# APM32F00x register map
File version: 1.0
CPU: CM0+ r0p1, little endian, no MPU, no FPU, 4 interrupt priority bits
Registers are 32-bit, read-write, reset 0x0 unless marked. A register's access mark holds for its fields unless they carry their own. Offsets are from the block's base; [hi:lo] are bit positions.

## USART1 — Universal asynchronous receiver transmitter
Base 0x40003400
Same registers: USART2 0x40001400, USART3 0x40004800
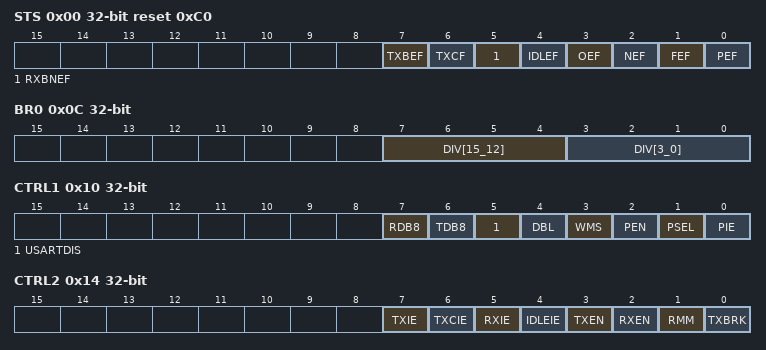
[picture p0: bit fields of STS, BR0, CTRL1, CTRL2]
0x00 STS access per field reset 0xC0 — Status register
  [7] TXBEF ro — Transmit data register empty
  [6] TXCF rw — Transmission complete
  [5] RXBNEF rw — Read data register not empty
  [4] IDLEF ro — IDLE line detected
  [3] OEF ro — Overrun error
  [2] NEF ro — Noise error flag
  [1] FEF ro — Framing error
  [0] PEF ro — Parity error
0x04 DATA
  [7:0] DATA — Data value
0x08 BR1 — Baud rate register 1
  [7:0] DIV[11_4] — LSB mantissa of USARTxDIV [11:4] mask
0x0C BR0 — Baud rate register 2
  [7:4] DIV[15_12] — MSB mantissa of USARTxDIV [15:12] mask
  [3:0] DIV[3_0] — Fraction bits of USARTxDIV [3:0] mask
0x10 CTRL1 — Control register 1
  [7] RDB8 — Receive Data bit 8
  [6] TDB8 — Transmit data bit 8
  [5] USARTDIS — USARTx Disable (for low power consumption)
  [4] DBL — Word length mask
  [3] WMS — Wake-up method mask
  [2] PEN — Parity Control Enable mask
  [1] PSEL — USARTx Parity Selection
  [0] PIE — USARTx Parity Interrupt Enable mask
0x14 CTRL2 — Control register 2
  [7] TXIE — Transmit Buffer Empty Interrupt Enable
  [6] TXCIE — Transmit Complete Interrupt Enable
  [5] RXIE — Receive Buffer Not Empty Interrupt Enable
  [4] IDLEIE — IDLE Interrupt Enable
  [3] TXEN — Transmit Enable
  [2] RXEN — Receive Enable
  [1] RMM — Receive Mute Mode Enable
  [0] TXBRK — Transmit Break Frame
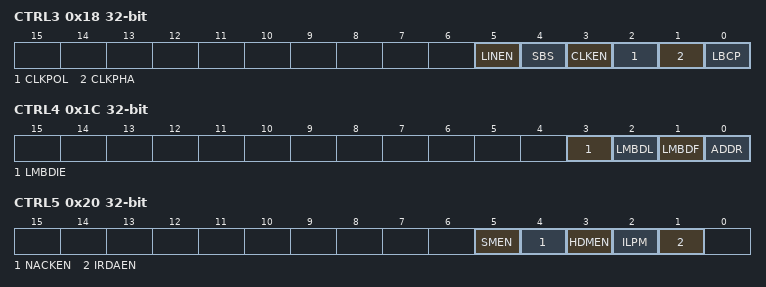
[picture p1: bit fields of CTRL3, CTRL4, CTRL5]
0x18 CTRL3 — Control register 3
  [5] LINEN — LIN Mode Enable
  [4] SBS — STOP Bit Configure
  [3] CLKEN — Clock Enable（CK pin）
  [2] CLKPOL — Clock Polarity Configure
  [1] CLKPHA — Clock Phase Configure
  [0] LBCP — Last Bit Clock Pulse Output Enable
0x1C CTRL4 — Control register 4
  [3] LMBDIE — LIN Break Detection Interrupt Enable
  [2] LMBDL — LIN Break Detection Length Configure
  [1] LMBDF — LIN Break Detected Flag
  [0] ADDR — USART Device Node Address Setup
0x20 CTRL5 — Control register 5
  [5] SMEN — Smartcard Function Enable
  [4] NACKEN — NACK Transmit Enable During Parity Error in Smartcard Function
  [3] HDMEN — Half-duplex Mode Enable
  [2] ILPM — IrDA Low-power Mode Enable
  [1] IRDAEN — IrDA Function Enable
0x24 GTS — Guard time and register
  [15:8] GTS — Guard Time Value Setup
0x28 PSC — USART1 prescaler register
  [15:8] PSC — Prescaler Factor Setup
0x2C SW — USART2/USART3 switch register
  [0] SW — Open USART
0x30 IOSW — USART3 IO switch register
  [0] SW — Open USART IO Port

## I2C — Inter-integrated circuit interface
Base 0x40003000
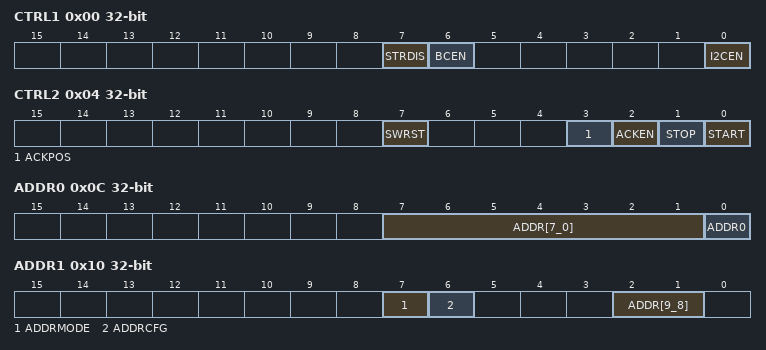
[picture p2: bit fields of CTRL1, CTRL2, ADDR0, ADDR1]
0x00 CTRL1 — Control register 1
  [7] STRDIS — Slave Mode Clock Stretching Disable
  [6] BCEN — Slave Responds Broadcast Enable
  [0] I2CEN — I2C Enable
0x04 CTRL2 — Control register 2
  [7] SWRST — Software Configure I2C under Reset State
  [3] ACKPOS — Acknowledge Position Configure
  [2] ACKEN — Acknowledge Transfer Enable
  [1] STOP — Stop Bit Transfer
  [0] START — Start Bit Transfer
0x08 CLKFREQ — Frequency Control register
  [5:0] FREQ — I2C Clock Frequency Configure
0x0C ADDR0 — Slave address register 0
  [7:1] ADDR[7_0] — Slave Address Setup
  [0] ADDR0 — Slave Address Setup
0x10 ADDR1 — Slave address register 1
  [7] ADDRMODE — Slave Address Mode Configure
  [6] ADDRCFG — Address Mode Configure
  [2:1] ADDR[9_8] — Slave Address Setup
0x18 DATA
  [7:0] DATA
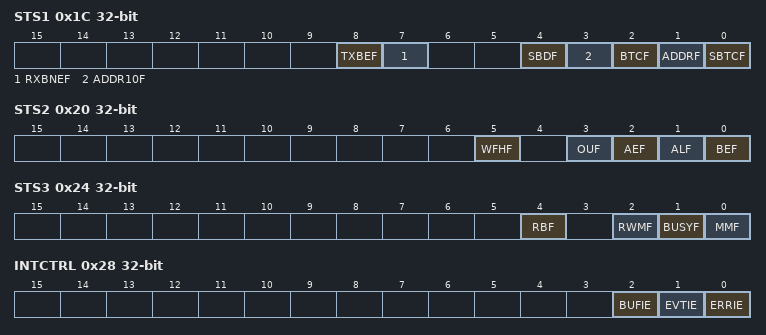
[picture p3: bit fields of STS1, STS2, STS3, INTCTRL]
0x1C STS1 ro — Status register 1
  [8] TXBEF — Transmit Buffer Empty Flag
  [7] RXBNEF — Receive Buffer Not Empty Flag
  [4] SBDF — Stop Bit Detection Flag
  [3] ADDR10F — 10-Bit Address Header Sent Flag
  [2] BTCF — Byte Transfer Complete Flag
  [1] ADDRF — Address Transfer Complete /Receive Match Flag
  [0] SBTCF — Start Bit Sent Finished Flag
0x20 STS2 ro — Status register 2
  [5] WFHF — Halt Mode Wakeup Flag
  [3] OUF — Overrun /Underrun Flag
  [2] AEF — Acknowledge Error Flag
  [1] ALF — Master Mode Arbitration Lost Flag
  [0] BEF — Bus Error Flag
0x24 STS3 ro — Status register 3
  [4] RBF — Slave Mode Received General Call Address Flag
  [2] RWMF — Transmitter / Receiver Mode Flag
  [1] BUSYF — Bus Busy Flag
  [0] MMF — Master Slave Mode Flag
0x28 INTCTRL — Interrupt control register
  [2] BUFIE — Buffer Interrupt Enable
  [1] EVTIE — Event Interrupt Enable
  [0] ERRIE — Error Interrupt Enable
0x2C CLKCTRL1 — Clock control register 1
  [7:0] CLKCTRL — Clock Setup in Fast/Standard Master Mode
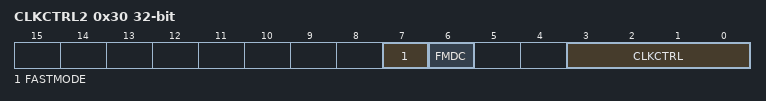
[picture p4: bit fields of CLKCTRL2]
0x30 CLKCTRL2 — Clock control register 2
  [7] FASTMODE — Master Mode Speed Configure
  [6] FMDC — Fast Mode Duty Cycle Configure
  [3:0] CLKCTRL — Clock Setup in Fast/Standard Master Mode
0x34 MRT reset 0x2 — Max Rise time register
  [5:0] MRT — Master Mode Maximum Rise Time in Fast/Standard Mode
